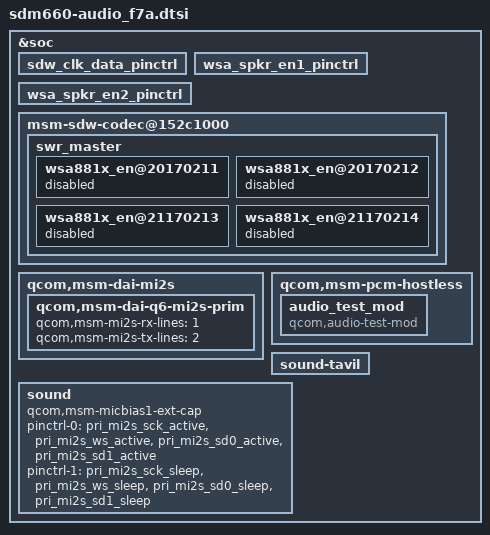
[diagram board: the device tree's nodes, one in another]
/* Copyright (c) 2016-2017, The Linux Foundation. All rights reserved.
 * Copyright (C) 2019 XiaoMi, Inc.
 * Copyright (c) 2020 Erik Castricum
 *
 * This program is free software; you can redistribute it and/or modify
 * it under the terms of the GNU General Public License version 2 and
 * only version 2 as published by the Free Software Foundation.
 *
 * This program is distributed in the hope that it will be useful,
 * but WITHOUT ANY WARRANTY; without even the implied warranty of
 * MERCHANTABILITY or FITNESS FOR A PARTICULAR PURPOSE.  See the
 * GNU General Public License for more details.
 */

&soc {
	sdw_clk_data_pinctrl {
		/delete-property/ pinctrl-names;
		/delete-property/ pinctrl-0;
		/delete-property/ pinctrl-1;
	};

	wsa_spkr_en1_pinctrl {
		/delete-property/ pinctrl-names;
		/delete-property/ pinctrl-0;
		/delete-property/ pinctrl-1;
	};

	wsa_spkr_en2_pinctrl {
		/delete-property/ pinctrl-names;
		/delete-property/ pinctrl-0;
		/delete-property/ pinctrl-1;
	};

	msm-sdw-codec@152c1000 {
		/delete-property/ qcom,cdc-sdw-gpios;
		swr_master {
			wsa881x_en@20170211 {
				status = "disabled";
			};

			wsa881x_en@20170212 {
				status = "disabled";
			};

			wsa881x_en@21170213 {
				status = "disabled";
			};

			wsa881x_en@21170214 {
				status = "disabled";
			};
		};
	};

	qcom,msm-dai-mi2s {
		qcom,msm-dai-q6-mi2s-prim {
			qcom,msm-mi2s-rx-lines = <1>;
			qcom,msm-mi2s-tx-lines = <2>;
		};
	};

	qcom,msm-pcm-hostless {
		audio_test_mod {
			compatible = "qcom,audio-test-mod";
		};
	};

	sound-tavil {
		/delete-property/ qcom,usbc-analog-en1_gpio;
		/delete-property/ qcom,usbc-analog-en2_n_gpio;
	};
	sound {
		qcom,msm-micbias1-ext-cap;
		/delete-property/ qcom,msm-micbias2-ext-cap;
		/delete-property/ qcom,us-euro-gpios;
		pinctrl-names = "pri_i2s_active", "pri_i2s_sleep";
		pinctrl-0 = <&pri_mi2s_sck_active &pri_mi2s_ws_active
				&pri_mi2s_sd0_active &pri_mi2s_sd1_active>;
		pinctrl-1 = <&pri_mi2s_sck_sleep &pri_mi2s_ws_sleep
				&pri_mi2s_sd0_sleep &pri_mi2s_sd1_sleep>;
	};

};
